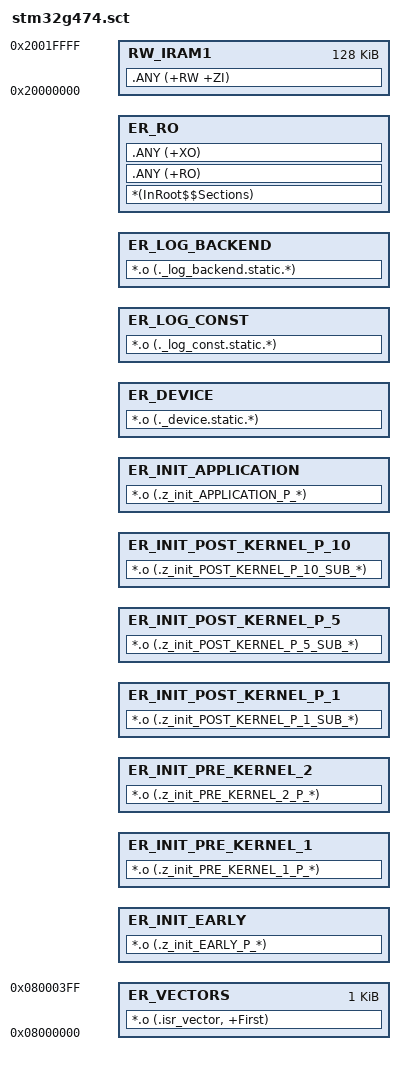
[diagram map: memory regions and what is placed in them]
; SPDX-License-Identifier: BSD-3-Clause
;
; STM32G474 scatter file (armlink, armclang AC6).
;
; This is the init-section ordering contract (see research ticket #2):
;   - Each init level lives in its own execution region, so level order equals
;     region order (ER_INIT_EARLY -> ... -> ER_INIT_APPLICATION).
;   - The reduced firmware uses POST_KERNEL priorities 1, 5, and 10. Separate
;     regions establish numeric order because armlink preserves input section
;     order rather than sorting these section names.
;   - `lib/utils/init_runner.c` walks each level and the ordered POST_KERNEL
;     regions using their Image$$ER_INIT_*$$Base / $$Limit symbols.
;
; Flash: 512 KB (0x08000000..0x08080000). RAM: 128 KB (0x20000000..0x20020000).

LR_IROM1 0x08000000 0x00080000 {
  ER_VECTORS 0x08000000 0x00000400 {
    *.o (.isr_vector, +First)
  }

  ER_INIT_EARLY +0 {
    *.o (.z_init_EARLY_P_*)
  }

  ER_INIT_PRE_KERNEL_1 +0 {
    *.o (.z_init_PRE_KERNEL_1_P_*)
  }

  ER_INIT_PRE_KERNEL_2 +0 {
    *.o (.z_init_PRE_KERNEL_2_P_*)
  }

  ER_INIT_POST_KERNEL_P_1 +0 {
    *.o (.z_init_POST_KERNEL_P_1_SUB_*)
  }

  ER_INIT_POST_KERNEL_P_5 +0 {
    *.o (.z_init_POST_KERNEL_P_5_SUB_*)
  }

  ER_INIT_POST_KERNEL_P_10 +0 {
    *.o (.z_init_POST_KERNEL_P_10_SUB_*)
  }

  ER_INIT_APPLICATION +0 {
    *.o (.z_init_APPLICATION_P_*)
  }

  ER_DEVICE +0 {
    *.o (._device.static.*)
  }

  ER_LOG_CONST +0 {
    *.o (._log_const.static.*)
  }

  ER_LOG_BACKEND +0 {
    *.o (._log_backend.static.*)
  }

  ER_RO +0 {
    *(InRoot$$Sections)
    .ANY (+RO)
    .ANY (+XO)
  }

  RW_IRAM1 0x20000000 0x00020000 {
    .ANY (+RW +ZI)
  }
}
